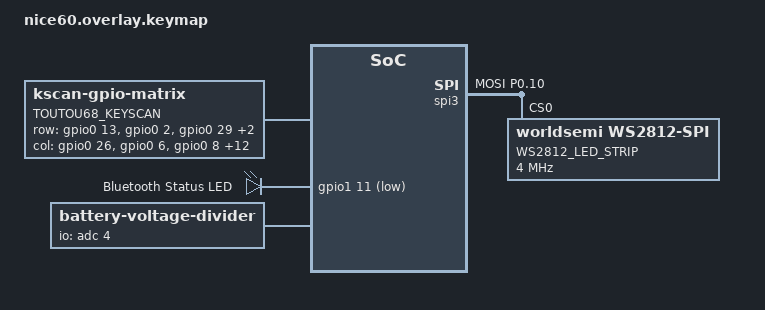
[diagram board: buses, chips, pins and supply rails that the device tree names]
/*
 * toutou68 键盘硬件配置文件
 * 文件名: toutou68.overlay (需放置在 zmk-config/config/ 目录下)
 * 功能: 重定义键盘矩阵、RGB灯效、电池检测等硬件配置
 */

#include <dt-bindings/led/led.h>
#include <dt-bindings/gpio/gpio.h>

/ {
    /* 系统选择节点 - 告知ZMK使用哪些硬件驱动 */
    chosen {
        /* 键盘矩阵扫描驱动 */
        zmk,kscan = &kscan0;
        /* RGB底灯驱动 */
        zmk,underglow = &led_strip;
        /* 电池电量检测驱动 */
        zmk,battery = &vbatt;
        zmk,ble-status-led = &led_ble_status;   /* <--- 新增 */
    };

    /* 键盘矩阵扫描配置 - 5行 x 15列 矩阵 */
    kscan0: kscan {
        compatible = "zmk,kscan-gpio-matrix";
        label = "TOUTOU68_KEYSCAN";
        
        /* 二极管方向: 行到列 (row2col) 或 列到行 (col2row) 
         * 需根据PCB实际电路确定, 常用 col2row */
        diode-direction = "col2row";
        
        /* 行引脚定义 (5行)
         * 格式: <&gpio端口 引脚号 标志>
         * GPIO_ACTIVE_HIGH: 高电平有效
         * GPIO_PULL_DOWN: 内部下拉电阻
         */
        row-gpios
            = <&gpio0 13 (GPIO_ACTIVE_HIGH | GPIO_PULL_DOWN)>  /* 行0 - 引脚113 (P0.13) */
            , <&gpio0 2  (GPIO_ACTIVE_HIGH | GPIO_PULL_DOWN)>  /* 行1 - 引脚002 (P0.02) */
            , <&gpio0 29 (GPIO_ACTIVE_HIGH | GPIO_PULL_DOWN)>  /* 行2 - 引脚029 (P0.29) */
            , <&gpio0 31 (GPIO_ACTIVE_HIGH | GPIO_PULL_DOWN)>  /* 行3 - 引脚031 (P0.31) */
            , <&gpio0 30 (GPIO_ACTIVE_HIGH | GPIO_PULL_DOWN)>; /* 行4 - 引脚030 (P0.30) */

        /* 列引脚定义 (15列)
         * 格式: <&gpio端口 引脚号 标志>
         * GPIO_ACTIVE_HIGH: 高电平有效
         * (列通常不需要内部上拉/下拉)
         */
        col-gpios
            = <&gpio0 26 (GPIO_ACTIVE_HIGH)>  /* 列0  - 引脚026 (P0.26) */
            , <&gpio0 6  (GPIO_ACTIVE_HIGH)>  /* 列1  - 引脚006 (P0.06) */
            , <&gpio0 8  (GPIO_ACTIVE_HIGH)>  /* 列2  - 引脚008 (P0.08) */
            , <&gpio0 12 (GPIO_ACTIVE_HIGH)>  /* 列3  - 引脚012 (P0.12) */
            , <&gpio1 9  (GPIO_ACTIVE_HIGH)>  /* 列4  - 引脚109 (P1.09) */
            , <&gpio0 15 (GPIO_ACTIVE_HIGH)>  /* 列5  - 引脚015 (P0.15) */
            , <&gpio0 17 (GPIO_ACTIVE_HIGH)>  /* 列6  - 引脚017 (P0.17) */
            , <&gpio0 20 (GPIO_ACTIVE_HIGH)>  /* 列7  - 引脚020 (P0.20) */
            , <&gpio0 22 (GPIO_ACTIVE_HIGH)>  /* 列8  - 引脚022 (P0.22) */
            , <&gpio0 10 (GPIO_ACTIVE_HIGH)>  /* 列9  - 引脚010 (P0.10) */
            , <&gpio0 13 (GPIO_ACTIVE_HIGH)>  /* 列10 - 引脚013 (P0.13) */
            , <&gpio0 24 (GPIO_ACTIVE_HIGH)>  /* 列11 - 引脚024 (P0.24) */
            , <&gpio1 10 (GPIO_ACTIVE_HIGH)>  /* 列12 - 引脚110 (P1.10) */
            , <&gpio0 28 (GPIO_ACTIVE_HIGH)>  /* 列13 - 引脚028 (P0.28) */
            , <&gpio0 3  (GPIO_ACTIVE_HIGH)>; /* 列14 - 引脚003 (P0.03) */
    };

/* 新增：蓝牙状态指示灯 */
    leds {
        compatible = "gpio-leds";
        led_ble_status: led_ble_status {
            label = "Bluetooth Status LED";
            gpios = <&gpio1 11 GPIO_ACTIVE_LOW>;
        };
    };


    /* 电池电量检测配置 - 使用ADC读取电池电压 */
    vbatt: vbatt {
        compatible = "zmk,battery-voltage-divider";
        label = "BATTERY";
        /* 电池分压电路配置
         * 需根据PCB上的实际电阻分压比设置
         * output-ohms: 分压器下端电阻阻值 (单位: 欧姆)
         * full-ohms: 分压器总电阻阻值 (上端+下端)
         * 示例: 若电阻为 1MΩ + 1MΩ, 则分压比为 1/2
         *       output-ohms = <1000000>;
         *       full-ohms = <2000000>;
         */
        output-ohms = <1000000>;
        full-ohms = <2000000>;
        /* ADC采样引脚 - 引脚004 (P0.04) */
        io-channels = <&adc 4>;
    };
};

/* 引脚控制配置 - 用于SPI/I2C等外设 */
&pinctrl {
    /* SPI3 默认状态引脚定义 (活跃状态) */
    spi3_default: spi3_default {
        group1 {
            /* MOSI引脚配置: 使用 P0.10 作为WS2812数据引脚 */
            psels = <NRF_PSEL(SPIM_MOSI, 0, 10)>;
        };
    };
    
    /* SPI3 睡眠状态引脚定义 (低功耗状态) */
    spi3_sleep: spi3_sleep {
        group1 {
            psels = <NRF_PSEL(SPIM_MOSI, 0, 10)>;
            /* 低功耗模式下使能 */
            low-power-enable;
        };
    };
};

/* SPI3 总线配置 - 用于驱动WS2812 RGB LED */
&spi3 {
    compatible = "nordic,nrf-spim";
    status = "okay";
    
    /* 关联引脚控制配置 */
    pinctrl-0 = <&spi3_default>;
    pinctrl-1 = <&spi3_sleep>;
    pinctrl-names = "default", "sleep";
    
    /* WS2812 LED灯带配置 */
    led_strip: ws2812@0 {
        compatible = "worldsemi,ws2812-spi";
        label = "WS2812_LED_STRIP";
        
        /* SPI寄存器地址 - 固定值 */
        reg = <0>;
        /* SPI时钟频率 - 4MHz (WS2812推荐值) */
        spi-max-frequency = <4000000>;
        
        /* LED数量 - 根据实际PCB上的灯珠数量修改 */
        chain-length = <68>;
        
        /* WS2812通信时序定义 */
        spi-one-frame = <0x70>;   /* 1码: 高电平占空比 ~70% */
        spi-zero-frame = <0x40>;  /* 0码: 高电平占空比 ~40% */
        
        /* 颜色通道映射 (WS2812标准顺序: GRB)
         * 若LED颜色显示异常, 可调整此顺序 */
        color-mapping = <LED_COLOR_ID_GREEN 
                         LED_COLOR_ID_RED 
                         LED_COLOR_ID_BLUE>;
    };
};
